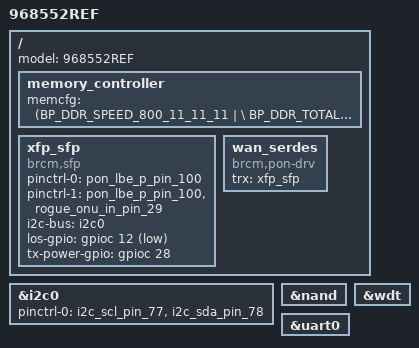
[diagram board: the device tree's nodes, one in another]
#include "inc/68552.dtsi"

/ {
	memory_controller {
		memcfg = <(BP_DDR_SPEED_800_11_11_11 | \
					BP_DDR_TOTAL_SIZE_256MB  | \
					BP_DDR_DEVICE_WIDTH_8    | \
					BP_DDR_TOTAL_WIDTH_8BIT)>;
	};
};

/ {
	model = "968552REF";

    xfp_sfp: xfp_sfp {
        compatible = "brcm,sfp";
        pinctrl-names = "default", "tx-sd";
        pinctrl-0 = <&pon_lbe_p_pin_100>;
        pinctrl-1 = <&pon_lbe_p_pin_100 &rogue_onu_in_pin_29>;
        i2c-bus = <&i2c0>;
        los-gpio = <&gpioc 12 GPIO_ACTIVE_LOW>;
        tx-power-gpio = <&gpioc 28 GPIO_ACTIVE_HIGH>;
    };

    wan_serdes {
            compatible = "brcm,pon-drv";
            trx = <&xfp_sfp>;
    };

};

&i2c0 {
    pinctrl-0 = <&i2c_scl_pin_77 &i2c_sda_pin_78>;
    pinctrl-names = "default";
    status = "okay";
};
&nand {
	status = "okay";
};
&wdt {
	status = "okay";
};
&uart0 {
	status = "okay";
};
